# liliumSOC1_secure register map
Vendor: Nordic Semiconductor; Series: liliumSOC1; File version: 1
CPU: CM33 r0p4, little endian, MPU, FPU, 3 interrupt priority bits, 480 interrupts, 4 SAU regions
Registers are 32-bit, read-write, reset 0x0 unless marked. A register's access mark holds for its fields unless they carry their own. Offsets are from the block's base; [hi:lo] are bit positions; lines under a group give offsets from that group; {n}, {i} and the like mark numbered series; 'fields as' and 'values as' point back to an identical list.

## MUTEX_NS — MUTEX 0
Base 0x41017000
Same registers: MUTEX_S 0x51017000
{0x400+4i} MUTEX[{i}] (i=0..7) — Description collection: Mutex register
  [0] MUTEX — Mutex register n
    0=Unlocked (Mutex n is in unlocked state); 1=Locked (Mutex n is in locked state)

## BILS_S — The Built-in Leakage Sensor (BILS) module.
Base 0x51019000
0x400 CONFIG group — Unspecified
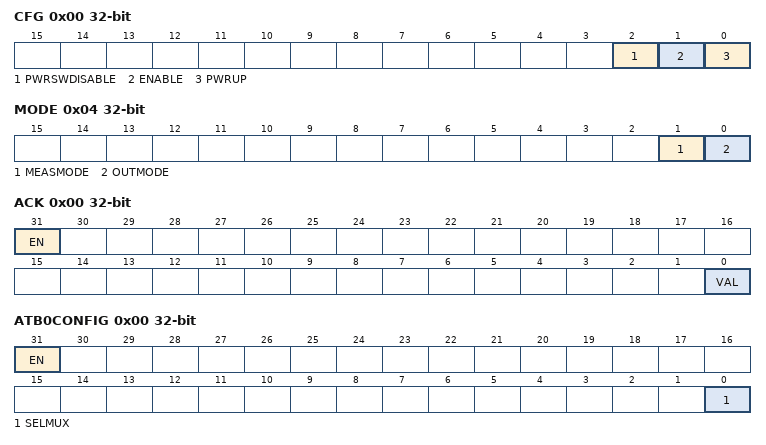
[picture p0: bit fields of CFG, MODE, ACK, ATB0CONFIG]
  0x00 CFG — BILS configuration
    [2] PWRSWDISABLE — Disable power switch.
      0=PwrSwNormalMode (Normal control of the power switch.); 1=PwrSwDisabledMode (Power switch is turned off.)
    [1] ENABLE — BILS enable
      0=BilsDisable (Disable BILS, REQ_SWOFF_AO_0V8 = 0); 1=BilsEnable (Enable BILS, REQ_SWOFF_AO_0V8 is controlled by BILS)
    [0] PWRUP — Power up BILS
      0=PwrOff (BILS is powered down and REQ_SWOFF_AO_0V8=0); 1=PwrOn (BILS is powered up)
  0x04 MODE — Mode selection
    [1] MEASMODE — Measurement mode selection
      0=MeasDisMode (Measure discharge rate); 1=MeasPwMode (Measure power switch chain propagation delay)
    [0] OUTMODE — Output mode selection
      0=Duty50Mode (50:50 duty cycle output selected to FOUT_AO_0V8 pin); 1=CompMode (Comparator output selected to FOUT_AO_0V8 pin)
0x500 OVERRIDE group — Unspecified
  0x00 ACK — Override the ACL_SWOFF_0V8 signal
    [31] EN — Override enable
      0=Disabled (Override disabled); 1=Enabled (Override is enabled)
    [0] VAL — Override value
0x600 DFT group — Unspecified
  0x00 ATB0CONFIG — Analog Test Bus 0 (ATB0) configuration
    [31] EN — Enable the analog test bus
      0=Disabled (Analog test bus is disabled); 1=Enabled (Analog test bus is enabled)
    [0] SELMUX — Select multiplexer for ATB0
      0=None selected; 1=Connect (Voltage on ATB0 used as threshold voltage)
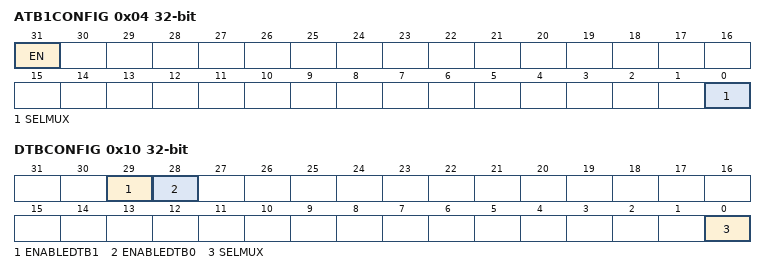
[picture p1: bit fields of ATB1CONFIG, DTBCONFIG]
  0x04 ATB1CONFIG — Analog Test Bus 1 (ATB1) configuration
    [31] EN — Enable the analog test bus
      values as DFT.ATB0CONFIG.EN
    [0] SELMUX — Select multiplexer for ATB1
      0=None selected; 1=ConnectDVDD (ATB1 connected to DVDD_0V8_SW)
  0x10 DTBCONFIG — Digital Test Bus configuration
    [29] ENABLEDTB1 — Enable the digital test bus
      0=Disabled (Digital test bus is disabled); 1=Enabled (Digital test bus is enabled)
    [28] ENABLEDTB0 — Enable the digital test bus
      values as ENABLEDTB1
    [0] SELMUX — Select multiplexer for DTB0
      0=None selected; 1=Connect (FOUT_AO_0V8 is connected to DTB0, REQ_SWOFF_AO_0V8 is connected to DTB1)

## RESETINFO_S — RESETINFO
Base 0x5101E000; alternate view of LRCCONF010_S
0x4C0 RESTOREVALID write-1-clears — Valid restore image is present in RAM.
  [0] RESTOREVALID
    0=NotPreset (Not present); 1=Present
0x4C4 MASKLOCKUP — Mask CPU lockup signal.
  [0] MASK — Mask lockup signal
    0=NotMask (Do not mask lockup signal); 1=Mask lockup signal

## BELLBOARD_NS — BELLBOARD APB registers 0
Base 0x4F099000
Same registers: BELLBOARD_S 0x5F099000
{0x0+4i} TASKS_TRIGGER[{i}] (i=0..31) wo — Description collection: Task TRIGGER[n]
  [0] TASKS_TRIGGER — Task TRIGGER[n]
    1=Trigger task
{0x100+4i} EVENTS_TRIGGERED[{i}] (i=0..31) — Description collection: Event TRIGGERED[n]
  [0] EVENTS_TRIGGERED — Event TRIGGERED[n]
    0=NotGenerated (Event not generated); 1=Generated (Event generated)
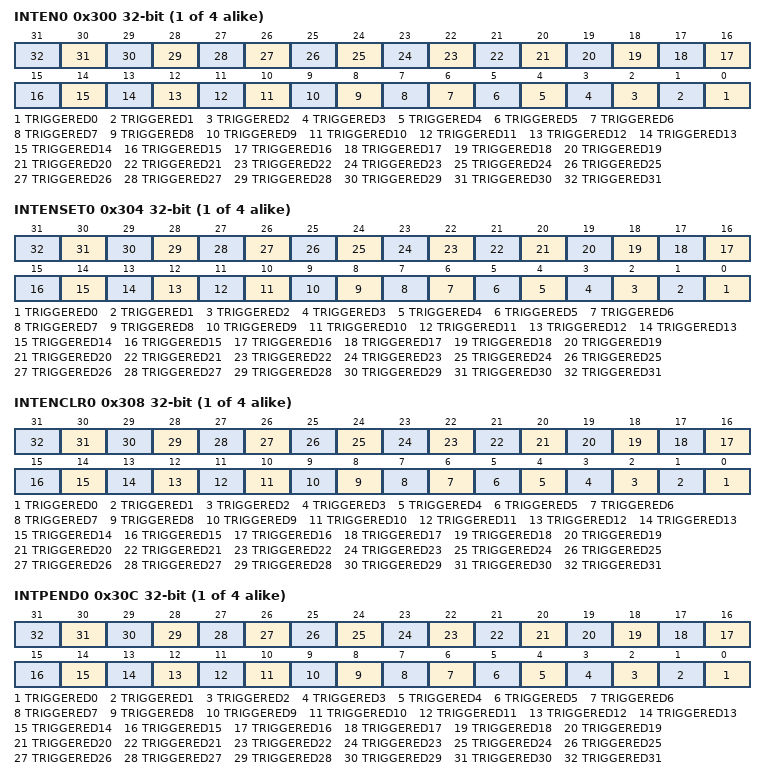
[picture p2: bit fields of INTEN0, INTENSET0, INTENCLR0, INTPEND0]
{0x300+0x10*i} INTEN{i} (i=0..3) — Enable or disable interrupt
  [all] fields
    0=Disabled; 1=Enabled
  [n] TRIGGERED{n} (n=0..31) — Enable or disable interrupt for event TRIGGERED[{n}]
{0x304+0x10*i} INTENSET{i} (i=0..3) — Enable interrupt
  [all] fields
    on read: 0=Disabled (Read: Disabled); 1=Enabled (Read: Enabled) | on write: 1=Set (Enable)
  [n] TRIGGERED{n} (n=0..31) — Write '1' to enable interrupt for event TRIGGERED[{n}]
{0x308+0x10*i} INTENCLR{i} (i=0..3) — Disable interrupt
  [all] fields
    on read: 0=Disabled (Read: Disabled); 1=Enabled (Read: Enabled) | on write: 1=Clear (Disable)
  [n] TRIGGERED{n} (n=0..31) — Write '1' to disable interrupt for event TRIGGERED[{n}]
{0x30C+0x10*i} INTPEND{i} ro (i=0..3) — Pending interrupts
  [all] fields
    on read: 0=NotPending (Read: Not pending); 1=Pending (Read: Pending)
  [n] TRIGGERED{n} (n=0..31) — Read pending status of interrupt for event TRIGGERED[{n}]
